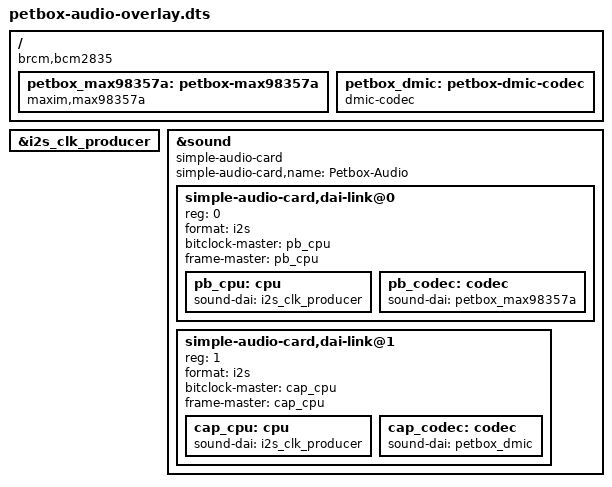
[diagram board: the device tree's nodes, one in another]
/dts-v1/;
/plugin/;

/ {
    compatible = "brcm,bcm2835";

    fragment@0 {
        target = <&i2s_clk_producer>;
        __overlay__ {
            status = "okay";
        };
    };

    fragment@1 {
        target-path = "/";
        __overlay__ {
            petbox_max98357a: petbox-max98357a {
                compatible = "maxim,max98357a";
                #sound-dai-cells = <0>;
                status = "okay";
            };
        };
    };

    fragment@2 {
        target-path = "/";
        __overlay__ {
            petbox_dmic: petbox-dmic-codec {
                compatible = "dmic-codec";
                #sound-dai-cells = <0>;
                status = "okay";
            };
        };
    };

    fragment@3 {
        target = <&sound>;
        __overlay__ {
            compatible = "simple-audio-card";
            status = "okay";
            #address-cells = <1>;
            #size-cells = <0>;
            simple-audio-card,name = "Petbox-Audio";

            simple-audio-card,dai-link@0 {
                reg = <0>;
                format = "i2s";
                bitclock-master = <&pb_cpu>;
                frame-master = <&pb_cpu>;

                pb_cpu: cpu {
                    sound-dai = <&i2s_clk_producer>;
                };

                pb_codec: codec {
                    sound-dai = <&petbox_max98357a>;
                };
            };

            simple-audio-card,dai-link@1 {
                reg = <1>;
                format = "i2s";
                bitclock-master = <&cap_cpu>;
                frame-master = <&cap_cpu>;

                cap_cpu: cpu {
                    sound-dai = <&i2s_clk_producer>;
                };

                cap_codec: codec {
                    sound-dai = <&petbox_dmic>;
                };
            };
        };
    };

    __overrides__ {
        card-name = <&sound>,"simple-audio-card,name";
    };
};
